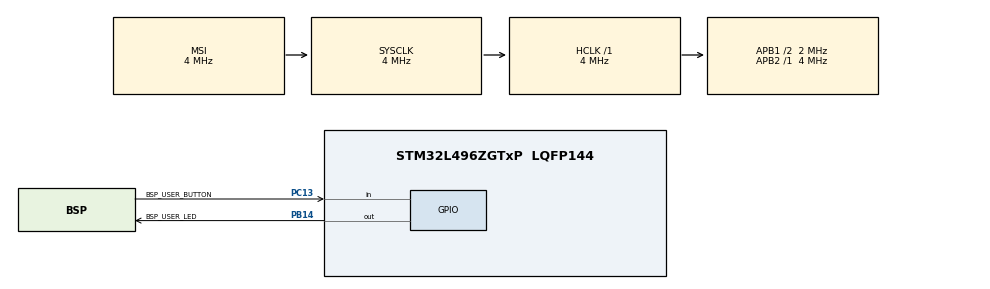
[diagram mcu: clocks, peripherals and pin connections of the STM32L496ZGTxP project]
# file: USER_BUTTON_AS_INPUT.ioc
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Mcu.Family=STM32L4
Mcu.Name=STM32L496ZGTxP
Mcu.Package=LQFP144
NVIC.PriorityGroup=NVIC_PRIORITYGROUP_4
PB14.GPIO_Label=BSP_USER_LED
PB14.Signal=GPIO_Output
PC13.GPIO_Label=BSP_USER_BUTTON
PC13.Signal=GPIO_Input
ProjectManager.HeapSize=0x200
ProjectManager.StackSize=0x400
ProjectManager.TargetToolchain=STM32CubeIDE
RCC.48MHZClocksFreq_Value=24000000
RCC.AHBFreq_Value=4000000
RCC.APB1CLKDivider=RCC_HCLK_DIV2
RCC.APB1Freq_Value=2000000
RCC.APB1TimFreq_Value=4000000
RCC.APB2Freq_Value=4000000
RCC.APB2TimFreq_Value=4000000
RCC.CortexFreq_Value=4000000
RCC.HCLKFreq_Value=4000000
RCC.HSE_VALUE=8000000
RCC.HSI48_VALUE=48000000
RCC.HSI_VALUE=16000000
RCC.LSE_VALUE=32768
RCC.MSI_VALUE=4000000
RCC.PLLMUL=RCC_PLL_MUL9
RCC.PRESCALERUSB=RCC_USBCLKSOURCE_PLL_DIV1_5
RCC.SYSCLKFreq_VALUE=4000000
RCC.SYSCLKSourceVirtual=RCC_SYSCLKSOURCE_PLLCLK
RCC.USBFreq_Value=16000000
RCC.VCOOutputFreq_Value=32000000
board=NUCLEO-L496ZG-P

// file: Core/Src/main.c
/* USER CODE BEGIN Header */
/**
  ******************************************************************************
  * @file           : main.c
  * @brief          : Main program body
  ******************************************************************************
  * @attention
  *
  * Copyright (c) 2024 STMicroelectronics.
  * All rights reserved.
  *
  * This software is licensed under terms that can be found in the LICENSE file
  * in the root directory of this software component.
  * If no LICENSE file comes with this software, it is provided AS-IS.
  *
  ******************************************************************************
  */
/* USER CODE END Header */
#include "main.h"

/* USER CODE BEGIN Includes */
#include "stdbool.h"
/* USER CODE END Includes */

/* USER CODE BEGIN PM */
#define BTN_DEBOUNCE_DELAY 500
/* USER CODE END PM */

/* USER CODE BEGIN PV */
static volatile bool flag;
/* USER CODE END PV */

void SystemClock_Config(void);
static void MX_GPIO_Init(void);

int main(void)
{

  /* MCU Configuration--------------------------------------------------------*/

  /* Reset of all peripherals, Initializes the Flash interface and the Systick. */
  HAL_Init();

  /* Configure the system clock */
  SystemClock_Config();

  /* Initialize all configured peripherals */
  MX_GPIO_Init();

  /* Infinite loop */
  while (1)
  {

    /* USER CODE BEGIN 3 */
	  //this is the method for operating led using switch
	  if(HAL_GPIO_ReadPin(GPIOC, BSP_USER_BUTTON_Pin)== GPIO_PIN_SET)
	  	  {
	  		  if(flag == false)
	  		  {
	  				HAL_GPIO_WritePin(GPIOB, BSP_USER_LED_Pin, GPIO_PIN_SET);
	  				flag = true;
	  		  }
	  		  else
	  		  {
	  				HAL_GPIO_WritePin(GPIOB, BSP_USER_LED_Pin, GPIO_PIN_RESET);
	  				flag = false;
	  		  }
	  		  HAL_Delay(BTN_DEBOUNCE_DELAY);
	  	  }

	  //we can use this method also
//	  if(HAL_GPIO_ReadPin(GPIOC, BSP_USER_BUTTON_Pin)== GPIO_PIN_SET)
//	  {
//		  HAL_GPIO_TogglePin(BSP_USER_LED_GPIO_Port, BSP_USER_LED_Pin);
//		  HAL_Delay(BTN_DEBOUNCE_DELAY);
//	  }

  }
  /* USER CODE END 3 */
}

void SystemClock_Config(void)
{
  RCC_OscInitTypeDef RCC_OscInitStruct = {0};
  RCC_ClkInitTypeDef RCC_ClkInitStruct = {0};

  /** Configure the main internal regulator output voltage
  */
  if (HAL_PWREx_ControlVoltageScaling(PWR_REGULATOR_VOLTAGE_SCALE1) != HAL_OK)
  {
    Error_Handler();
  }

  /** Initializes the RCC Oscillators according to the specified parameters
  * in the RCC_OscInitTypeDef structure.
  */
  RCC_OscInitStruct.OscillatorType = RCC_OSCILLATORTYPE_MSI;
  RCC_OscInitStruct.MSIState = RCC_MSI_ON;
  RCC_OscInitStruct.MSICalibrationValue = 0;
  RCC_OscInitStruct.MSIClockRange = RCC_MSIRANGE_6;
  RCC_OscInitStruct.PLL.PLLState = RCC_PLL_NONE;
  if (HAL_RCC_OscConfig(&RCC_OscInitStruct) != HAL_OK)
  {
    Error_Handler();
  }

  /** Initializes the CPU, AHB and APB buses clocks
  */
  RCC_ClkInitStruct.ClockType = RCC_CLOCKTYPE_HCLK|RCC_CLOCKTYPE_SYSCLK
                              |RCC_CLOCKTYPE_PCLK1|RCC_CLOCKTYPE_PCLK2;
  RCC_ClkInitStruct.SYSCLKSource = RCC_SYSCLKSOURCE_MSI;
  RCC_ClkInitStruct.AHBCLKDivider = RCC_SYSCLK_DIV1;
  RCC_ClkInitStruct.APB1CLKDivider = RCC_HCLK_DIV2;
  RCC_ClkInitStruct.APB2CLKDivider = RCC_HCLK_DIV1;

  if (HAL_RCC_ClockConfig(&RCC_ClkInitStruct, FLASH_LATENCY_0) != HAL_OK)
  {
    Error_Handler();
  }
}

static void MX_GPIO_Init(void)
{
  GPIO_InitTypeDef GPIO_InitStruct = {0};

  /* GPIO Ports Clock Enable */
  __HAL_RCC_GPIOC_CLK_ENABLE();
  __HAL_RCC_GPIOB_CLK_ENABLE();

  /*Configure GPIO pin Output Level */
  HAL_GPIO_WritePin(BSP_USER_LED_GPIO_Port, BSP_USER_LED_Pin, GPIO_PIN_RESET);

  /*Configure GPIO pin : BSP_USER_BUTTON_Pin */
  GPIO_InitStruct.Pin = BSP_USER_BUTTON_Pin;
  GPIO_InitStruct.Mode = GPIO_MODE_INPUT;
  GPIO_InitStruct.Pull = GPIO_NOPULL;
  HAL_GPIO_Init(BSP_USER_BUTTON_GPIO_Port, &GPIO_InitStruct);

  /*Configure GPIO pin : BSP_USER_LED_Pin */
  GPIO_InitStruct.Pin = BSP_USER_LED_Pin;
  GPIO_InitStruct.Mode = GPIO_MODE_OUTPUT_PP;
  GPIO_InitStruct.Pull = GPIO_NOPULL;
  GPIO_InitStruct.Speed = GPIO_SPEED_FREQ_LOW;
  HAL_GPIO_Init(BSP_USER_LED_GPIO_Port, &GPIO_InitStruct);

}

void Error_Handler(void)
{
  __disable_irq();
  while (1)
  {
  }
}
